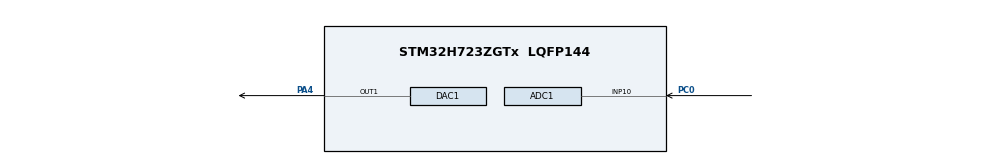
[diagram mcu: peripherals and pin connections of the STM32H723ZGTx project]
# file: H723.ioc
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ADC1.Channel-0\#ChannelRegularConversion=ADC_CHANNEL_10
ADC1.ClockPrescaler=ADC_CLOCK_ASYNC_DIV4
ADC1.ContinuousConvMode=DISABLE
ADC1.ConversionDataManagement=ADC_CONVERSIONDATA_DMA_CIRCULAR
ADC1.ExternalTrigConv=ADC_EXTERNALTRIG_T6_TRGO
ADC1.NbrOfConversionFlag=1
ADC1.OffsetNumber-0\#ChannelRegularConversion=ADC_OFFSET_NONE
ADC1.OffsetSignedSaturation-0\#ChannelRegularConversion=DISABLE
ADC1.Rank-0\#ChannelRegularConversion=1
ADC1.Resolution=ADC_RESOLUTION_12B
ADC1.SamplingTime-0\#ChannelRegularConversion=ADC_SAMPLETIME_8CYCLES_5
ADC1.master=1
CORTEX_M7.AccessPermission_Spec=MPU_REGION_FULL_ACCESS
CORTEX_M7.BaseAddress_Spec=0x24000000
CORTEX_M7.CPU_DCache=Enabled
CORTEX_M7.CPU_ICache=Enabled
CORTEX_M7.DisableExec_Spec=MPU_INSTRUCTION_ACCESS_ENABLE
CORTEX_M7.Enable_Spec=MPU_REGION_ENABLE
CORTEX_M7.IsShareable_Spec=MPU_ACCESS_NOT_SHAREABLE
CORTEX_M7.MPU_Control=MPU_HFNMI_PRIVDEF
CORTEX_M7.Size_Spec=MPU_REGION_SIZE_512KB
CORTEX_M7.SubRegionDisable_Spec=0x0
CORTEX_M7.TypeExtField_Spec=MPU_TEX_LEVEL1
CORTEX_M7.default_mode_Activation=1
DAC1.DAC_Channel-DAC_OUT1=DAC_CHANNEL_1
DAC1.DAC_Trigger-DAC_OUT1=DAC_TRIGGER_T6_TRGO
Dma.ADC1.0.Direction=DMA_PERIPH_TO_MEMORY
Dma.ADC1.0.EventEnable=DISABLE
Dma.ADC1.0.FIFOMode=DMA_FIFOMODE_DISABLE
Dma.ADC1.0.Instance=DMA1_Stream0
Dma.ADC1.0.MemDataAlignment=DMA_MDATAALIGN_HALFWORD
Dma.ADC1.0.MemInc=DMA_MINC_ENABLE
Dma.ADC1.0.Mode=DMA_CIRCULAR
Dma.ADC1.0.PeriphDataAlignment=DMA_PDATAALIGN_HALFWORD
Dma.ADC1.0.PeriphInc=DMA_PINC_DISABLE
Dma.ADC1.0.Polarity=HAL_DMAMUX_REQ_GEN_RISING
Dma.ADC1.0.Priority=DMA_PRIORITY_LOW
Dma.ADC1.0.RequestNumber=1
Dma.ADC1.0.SignalID=NONE
Dma.ADC1.0.SyncEnable=DISABLE
Dma.ADC1.0.SyncPolarity=HAL_DMAMUX_SYNC_NO_EVENT
Dma.ADC1.0.SyncRequestNumber=1
Dma.ADC1.0.SyncSignalID=NONE
Dma.DAC1_CH1.1.Direction=DMA_MEMORY_TO_PERIPH
Dma.DAC1_CH1.1.EventEnable=DISABLE
Dma.DAC1_CH1.1.FIFOMode=DMA_FIFOMODE_DISABLE
Dma.DAC1_CH1.1.Instance=DMA1_Stream1
Dma.DAC1_CH1.1.MemDataAlignment=DMA_MDATAALIGN_HALFWORD
Dma.DAC1_CH1.1.MemInc=DMA_MINC_ENABLE
Dma.DAC1_CH1.1.Mode=DMA_CIRCULAR
Dma.DAC1_CH1.1.PeriphDataAlignment=DMA_PDATAALIGN_HALFWORD
Dma.DAC1_CH1.1.PeriphInc=DMA_PINC_DISABLE
Dma.DAC1_CH1.1.Polarity=HAL_DMAMUX_REQ_GEN_RISING
Dma.DAC1_CH1.1.Priority=DMA_PRIORITY_LOW
Dma.DAC1_CH1.1.RequestNumber=1
Dma.DAC1_CH1.1.SignalID=NONE
Dma.DAC1_CH1.1.SyncEnable=DISABLE
Dma.DAC1_CH1.1.SyncPolarity=HAL_DMAMUX_SYNC_NO_EVENT
Dma.DAC1_CH1.1.SyncRequestNumber=1
Dma.DAC1_CH1.1.SyncSignalID=NONE
Dma.Request0=ADC1
Dma.Request1=DAC1_CH1
Mcu.Family=STM32H7
Mcu.Name=STM32H723ZGTx
Mcu.Package=LQFP144
NVIC.DMA1_Stream0_IRQn=true\:0\:0\:false\:false\:true\:false\:true\:true
NVIC.DMA1_Stream1_IRQn=true\:0\:0\:false\:false\:true\:false\:true\:true
NVIC.PriorityGroup=NVIC_PRIORITYGROUP_4
PA13(JTMS/SWDIO).Mode=Serial_Wire
PA13(JTMS/SWDIO).Signal=DEBUG_JTMS-SWDIO
PA14(JTCK/SWCLK).Mode=Serial_Wire
PA14(JTCK/SWCLK).Signal=DEBUG_JTCK-SWCLK
PA4.Signal=COMP_DAC11_group
PC0.Signal=ADCx_INP10
PC14-OSC32_IN.Mode=LSE-External-Oscillator
PC14-OSC32_IN.Signal=RCC_OSC32_IN
PC15-OSC32_OUT.Mode=LSE-External-Oscillator
PC15-OSC32_OUT.Signal=RCC_OSC32_OUT
PH0-OSC_IN.Mode=HSE-External-Oscillator
PH0-OSC_IN.Signal=RCC_OSC_IN
PH1-OSC_OUT.Mode=HSE-External-Oscillator
PH1-OSC_OUT.Signal=RCC_OSC_OUT
ProjectManager.HeapSize=0x200
ProjectManager.StackSize=0x400
ProjectManager.TargetToolchain=MDK-ARM V5.32
RCC.ADCFreq_Value=96000000
RCC.APB1Freq_Value=137500000
RCC.APB2Freq_Value=137500000
RCC.APB3Freq_Value=137500000
RCC.APB4Freq_Value=137500000
RCC.CortexFreq_Value=550000000
RCC.D1PPRE=RCC_APB3_DIV2
RCC.D2PPRE1=RCC_APB1_DIV2
RCC.D2PPRE2=RCC_APB2_DIV2
RCC.D3PPRE=RCC_APB4_DIV2
RCC.DIVM1=4
RCC.DIVM2=4
RCC.DIVN1=34
RCC.DIVN2=12
RCC.DIVP1=1
RCC.HCLKFreq_Value=275000000
RCC.HPRE=RCC_HCLK_DIV2
RCC.PLL2FRACN=0
RCC.PLL3FRACN=0
RCC.PLLFRACN=3072
RCC.SYSCLKFreq_VALUE=550000000
RCC.SYSCLKSource=RCC_SYSCLKSOURCE_PLLCLK
RCC.USBFreq_Value=275000000
SH.ADCx_INP10.0=ADC1_INP10,IN10-Single-Ended
SH.COMP_DAC11_group.0=DAC1_OUT1,DAC_OUT1
TIM6.AutoReloadPreload=TIM_AUTORELOAD_PRELOAD_ENABLE
TIM6.Period=275-1
TIM6.Prescaler=10-1
TIM6.TIM_MasterOutputTrigger=TIM_TRGO_UPDATE
VP_MEMORYMAP_VS_MEMORYMAP.Mode=CurAppReg
VP_TIM6_VS_ClockSourceINT.Mode=Enable_Timer
board=custom

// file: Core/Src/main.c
/* USER CODE BEGIN Header */
/**
  ******************************************************************************
  * @file           : main.c
  * @brief          : Main program body
  ******************************************************************************
  * @attention
  *
  * Copyright (c) 2026 STMicroelectronics.
  * All rights reserved.
  *
  * This software is licensed under terms that can be found in the LICENSE file
  * in the root directory of this software component.
  * If no LICENSE file comes with this software, it is provided AS-IS.
  *
  ******************************************************************************
  */
/* USER CODE END Header */
#include "main.h"
#include "adc.h"
#include "dac.h"
#include "dma.h"
#include "tim.h"
#include "gpio.h"

/* USER CODE BEGIN Includes */
#include <string.h>
/* USER CODE END Includes */

/* USER CODE BEGIN PD */
#define BUF_HALF  256   /* 每半个缓冲区的采样点数 */
/* USER CODE END PD */

/* USER CODE BEGIN PV */
/* 双缓冲: 前半部分被 DMA 填充/读取时，CPU 处理后半部分 */
__attribute__((section (".AXI_SRAM"))) uint16_t adc_buffer[2 * BUF_HALF];
__attribute__((section (".AXI_SRAM"))) uint16_t dac_buffer[2 * BUF_HALF];
uint64_t average = 0;
/* USER CODE END PV */

void SystemClock_Config(void);
static void MPU_Config(void);
/* USER CODE BEGIN PFP */
static void ProcessHalfBuffer(uint16_t *src, uint16_t *dst, uint32_t size);
/* USER CODE END PFP */

/* USER CODE BEGIN 0 */

/* ADC 12位右对齐[11:0] -> x0.5 -> DAC 12位左对齐[15:4] */
/* 满量程: ADC 4095 -> x0.5 -> DAC左对齐 0x7FF0 (DAC值2047, 半量程) */
static void ProcessHalfBuffer(uint16_t *src, uint16_t *dst, uint32_t size)
{

  for (uint32_t i = 0; i < size; i++)
  {
    dst[i] = (src[i] << 4) & 0xFFF0;
  }
}

/* ADC DMA 半传输完成（前半缓冲区就绪）*/
void HAL_ADC_ConvHalfCpltCallback(ADC_HandleTypeDef *hadc)
{
  if (hadc->Instance == ADC1)
  {
    ProcessHalfBuffer(adc_buffer, dac_buffer, BUF_HALF);
  }
}

/* ADC DMA 全传输完成（后半缓冲区就绪）*/
void HAL_ADC_ConvCpltCallback(ADC_HandleTypeDef *hadc)
{

  if (hadc->Instance == ADC1)
  {
    ProcessHalfBuffer(&adc_buffer[BUF_HALF], &dac_buffer[BUF_HALF], BUF_HALF);
  }
}

/* USER CODE END 0 */

int main(void)
{

  /* MPU Configuration--------------------------------------------------------*/
  MPU_Config();

  /* Enable the CPU Cache */

  /* Enable I-Cache---------------------------------------------------------*/
  SCB_EnableICache();

  /* Enable D-Cache---------------------------------------------------------*/
  SCB_EnableDCache();

  /* MCU Configuration--------------------------------------------------------*/

  /* Reset of all peripherals, Initializes the Flash interface and the Systick. */
  HAL_Init();

  /* Configure the system clock */
  SystemClock_Config();

  /* Initialize all configured peripherals */
  MX_GPIO_Init();
  MX_DMA_Init();
  MX_ADC1_Init();
  MX_TIM6_Init();
  MX_DAC1_Init();
  /* USER CODE BEGIN 2 */

  /* 调试模式: 保持 TIM6 在断点时继续计数 */
  DBGMCU->APB1LFZ1 &= ~DBGMCU_APB1LFZ1_DBG_TIM6;

  /* ADC 校准: STM32H7 上电后必须校准 */
  if (HAL_ADCEx_Calibration_Start(&hadc1, ADC_CALIB_OFFSET, ADC_SINGLE_ENDED) != HAL_OK)
  {
    Error_Handler();
  }

  /* ADC 缓冲区清零 */
  memset(adc_buffer, 0, sizeof(adc_buffer));

  /* 测试: 预填充 DAC 缓冲为锯齿波 (12位左对齐, 0x0000~0xFFF0) */
  /* 如果示波器能看到锯齿波，说明 DAC+TRGO+DMA 链路正常 */
  for (uint32_t i = 0; i < 2 * BUF_HALF; i++)
  {
    dac_buffer[i] = ((i * 16) & 0xFFF0);  /* 0, 0x10, 0x20, ... 0xFFF0 */
  }

  /* 启动 DAC DMA（先启动，保证首个触发时就有数据可输出）*/
  if (HAL_DAC_Start_DMA(&hdac1, DAC_CHANNEL_1,
                        (uint32_t *)dac_buffer, 2 * BUF_HALF,
                        DAC_ALIGN_12B_L) != HAL_OK)
  {
    Error_Handler();
  }
  /* 启动 ADC DMA，使能半传输和全传输中断 */
  if (HAL_ADC_Start_DMA(&hadc1, (uint32_t *)adc_buffer,
                        2 * BUF_HALF) != HAL_OK)
  {
    Error_Handler();
  }

  /* 启动 TIM6，开始触发 ADC 采样和 DAC 输出 */
  HAL_TIM_Base_Start(&htim6);

  /* USER CODE END 2 */

  /* Infinite loop */
  while (1)
  {

  }
}

void SystemClock_Config(void)
{
  RCC_OscInitTypeDef RCC_OscInitStruct = {0};
  RCC_ClkInitTypeDef RCC_ClkInitStruct = {0};

  /** Supply configuration update enable
  */
  HAL_PWREx_ConfigSupply(PWR_LDO_SUPPLY);

  /** Configure the main internal regulator output voltage
  */
  __HAL_PWR_VOLTAGESCALING_CONFIG(PWR_REGULATOR_VOLTAGE_SCALE0);

  while(!__HAL_PWR_GET_FLAG(PWR_FLAG_VOSRDY)) {}

  /** Initializes the RCC Oscillators according to the specified parameters
  * in the RCC_OscInitTypeDef structure.
  */
  RCC_OscInitStruct.OscillatorType = RCC_OSCILLATORTYPE_HSI;
  RCC_OscInitStruct.HSIState = RCC_HSI_DIV1;
  RCC_OscInitStruct.HSICalibrationValue = 64;
  RCC_OscInitStruct.PLL.PLLState = RCC_PLL_ON;
  RCC_OscInitStruct.PLL.PLLSource = RCC_PLLSOURCE_HSI;
  RCC_OscInitStruct.PLL.PLLM = 4;
  RCC_OscInitStruct.PLL.PLLN = 34;
  RCC_OscInitStruct.PLL.PLLP = 1;
  RCC_OscInitStruct.PLL.PLLQ = 2;
  RCC_OscInitStruct.PLL.PLLR = 2;
  RCC_OscInitStruct.PLL.PLLRGE = RCC_PLL1VCIRANGE_3;
  RCC_OscInitStruct.PLL.PLLVCOSEL = RCC_PLL1VCOWIDE;
  RCC_OscInitStruct.PLL.PLLFRACN = 3072;
  if (HAL_RCC_OscConfig(&RCC_OscInitStruct) != HAL_OK)
  {
    Error_Handler();
  }

  /** Initializes the CPU, AHB and APB buses clocks
  */
  RCC_ClkInitStruct.ClockType = RCC_CLOCKTYPE_HCLK|RCC_CLOCKTYPE_SYSCLK
                              |RCC_CLOCKTYPE_PCLK1|RCC_CLOCKTYPE_PCLK2
                              |RCC_CLOCKTYPE_D3PCLK1|RCC_CLOCKTYPE_D1PCLK1;
  RCC_ClkInitStruct.SYSCLKSource = RCC_SYSCLKSOURCE_PLLCLK;
  RCC_ClkInitStruct.SYSCLKDivider = RCC_SYSCLK_DIV1;
  RCC_ClkInitStruct.AHBCLKDivider = RCC_HCLK_DIV2;
  RCC_ClkInitStruct.APB3CLKDivider = RCC_APB3_DIV2;
  RCC_ClkInitStruct.APB1CLKDivider = RCC_APB1_DIV2;
  RCC_ClkInitStruct.APB2CLKDivider = RCC_APB2_DIV2;
  RCC_ClkInitStruct.APB4CLKDivider = RCC_APB4_DIV2;

  if (HAL_RCC_ClockConfig(&RCC_ClkInitStruct, FLASH_LATENCY_3) != HAL_OK)
  {
    Error_Handler();
  }
}

 /* MPU Configuration */

void MPU_Config(void)
{
  MPU_Region_InitTypeDef MPU_InitStruct = {0};

  /* Disables the MPU */
  HAL_MPU_Disable();

  /** Initializes and configures the Region and the memory to be protected
  */
  MPU_InitStruct.Enable = MPU_REGION_ENABLE;
  MPU_InitStruct.Number = MPU_REGION_NUMBER0;
  MPU_InitStruct.BaseAddress = 0x24000000;
  MPU_InitStruct.Size = MPU_REGION_SIZE_512KB;
  MPU_InitStruct.SubRegionDisable = 0x0;
  MPU_InitStruct.TypeExtField = MPU_TEX_LEVEL1;
  MPU_InitStruct.AccessPermission = MPU_REGION_FULL_ACCESS;
  MPU_InitStruct.DisableExec = MPU_INSTRUCTION_ACCESS_ENABLE;
  MPU_InitStruct.IsShareable = MPU_ACCESS_NOT_SHAREABLE;
  MPU_InitStruct.IsCacheable = MPU_ACCESS_NOT_CACHEABLE;
  MPU_InitStruct.IsBufferable = MPU_ACCESS_NOT_BUFFERABLE;

  HAL_MPU_ConfigRegion(&MPU_InitStruct);
  /* Enables the MPU */
  HAL_MPU_Enable(MPU_HFNMI_PRIVDEF);

}

void Error_Handler(void)
{
  __disable_irq();
  while (1)
  {
  }
}
